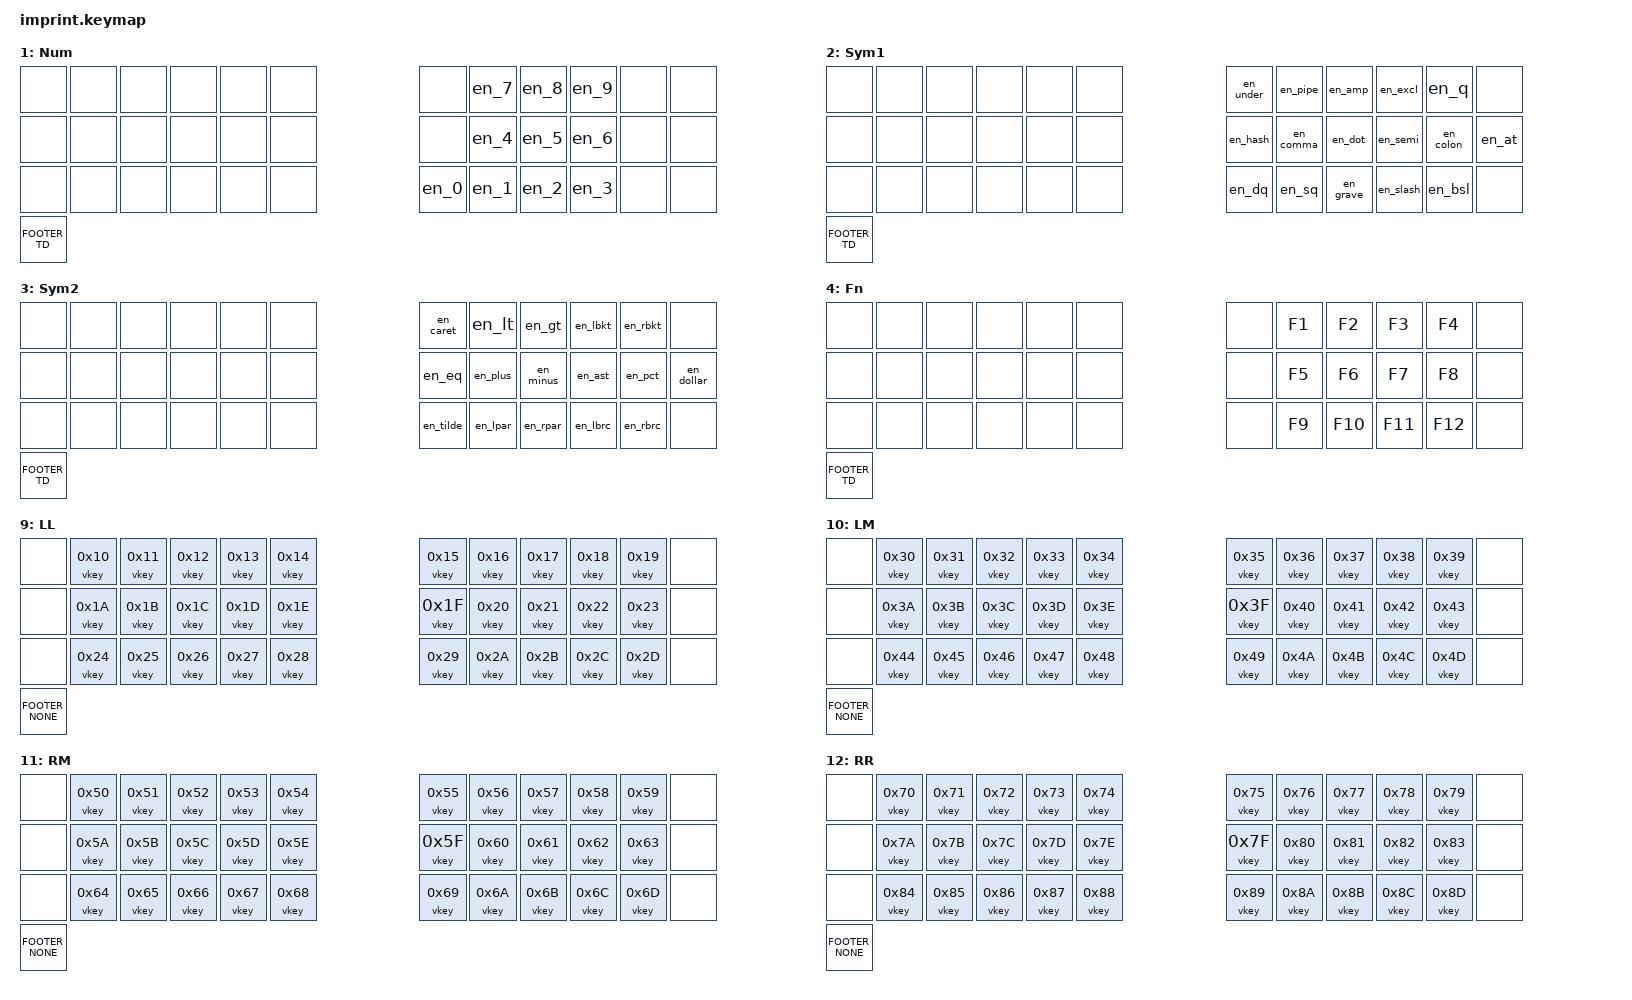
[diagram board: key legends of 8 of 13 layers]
#include <input/processors.dtsi>
#include <dt-bindings/zmk/input_transform.h>
#include <behaviors.dtsi>
#include <dt-bindings/zmk/keys.h>

#include "behavior_macros.h"

// https://github.com/zmkfirmware/zmk/pull/1811
&mt {
  hold-while-undecided;
};

// The left trackball always scrolls.
&trackball_central_listener {
  input-processors = TRACKBALL_SCROLL_PROCESSORS;
};

/ {
  chosen {
    zmk,matrix-transform = &imprint_letters_only_full_bottom_row;
  };
  combos {
    compatible = "zmk,combos";
    #include "combos.dtsi"
  };
  macros {
    #include "macros.dtsi"
  };
  behaviors {
    #include "imprint_behaviors.dtsi"
  };
  keymap {
    compatible = "zmk,keymap";

    // display-name matches [A-Za-z][A-Za-z0-9]{0,3} and is unique: only its
    // first 4 bytes reach the Prospector Dongle, and keymap-drawer silently
    // drops a layer whose name repeats. Canonical names, reasons and sources:
    // docs/glossary.md, entry "layer".
    DEFAULT_LAYER {
      display-name = "Base";
      bindings = <
        &kp EIJI    &al_q               &al_w              &al_e              &al_r             &al_t                    &al_y  &al_u     &al_i     &al_o      &al_p       &kp KANA
        &kp SPACE   &al_a               &al_s              &al_d              &al_f             &al_g                    &al_h  &al_j     &al_k     &al_l      &vkey 0x01     &kp BACKSPACE
        &kp ESCAPE  &al_z               &al_x              &al_c              &al_v             &al_b                    &al_n  &al_m     &ar_up    &kp TAB    &kp DELETE  &kp RETURN
        &none       MO_LAYER(FUNCTION)  MO_LAYER(SYMBOL2)  MO_LAYER(SYMBOL1)  MO_LAYER(NUMBER)                                  &ar_left  &ar_down  &ar_right  &none       &none
                                                               TU_LL  TU_LM  &none                    &none  TU_RM  TU_RR
                                                               TD_LL  TD_LM  &none                    &none  TD_RM  TD_RR
      >;
    };
    NUMBER_LAYER {
      display-name = "Num";
      bindings = <
        &none  &none  &none  &none  &none  &none                    &none  &en_7  &en_8  &en_9  &none  &none
        &none  &none  &none  &none  &none  &none                    &none  &en_4  &en_5  &en_6  &none  &none
        &none  &none  &none  &none  &none  &none                    &en_0  &en_1  &en_2  &en_3  &none  &none
        FOOTER_TD
      >;
    };
    SYMBOL1_LAYER {
      display-name = "Sym1";
      bindings = <
        &none  &none  &none  &none  &none  &none                    &en_under  &en_pipe   &en_amp    &en_excl   &en_q      &none
        &none  &none  &none  &none  &none  &none                    &en_hash   &en_comma  &en_dot    &en_semi   &en_colon  &en_at
        &none  &none  &none  &none  &none  &none                    &en_dq     &en_sq     &en_grave  &en_slash  &en_bsl    &none
        FOOTER_TD
      >;
    };
    SYMBOL2_LAYER {
      display-name = "Sym2";
      bindings = <
        &none  &none  &none  &none  &none  &none                    &en_caret  &en_lt    &en_gt     &en_lbkt  &en_rbkt  &none
        &none  &none  &none  &none  &none  &none                    &en_eq     &en_plus  &en_minus  &en_ast   &en_pct   &en_dollar
        &none  &none  &none  &none  &none  &none                    &en_tilde  &en_lpar  &en_rpar   &en_lbrc  &en_rbrc  &none
        FOOTER_TD
      >;
    };
    FUNCTION_LAYER {
      display-name = "Fn";
      bindings = <
        &none  &none  &none  &none  &none  &none                    &none  &kp F1  &kp F2   &kp F3   &kp F4   &none
        &none  &none  &none  &none  &none  &none                    &none  &kp F5  &kp F6   &kp F7   &kp F8   &none
        &none  &none  &none  &none  &none  &none                    &none  &kp F9  &kp F10  &kp F11  &kp F12  &none
        FOOTER_TD
      >;
    };
    // Arrow sub-layers, entered by holding an arrow key (ar_*). A display-name
    // names that arrow key (the node's *_ARROW), not what the layer sends,
    // which may change.
    LEFT_ARROW_LAYER {
      display-name = "LArr";
      bindings = <
        ROW_NONE
        ROW_NONE
        ROW_NONE
        &none  &none  &none  &none  &none                    &none  &kp HOME  &none  &none  &none
        THUMB_TD
      >;
    };
    RIGHT_ARROW_LAYER {
      display-name = "RArr";
      bindings = <
        ROW_NONE
        ROW_NONE
        ROW_NONE
        &none  &none  &none  &none  &none                    &none  &kp END  &none  &none  &none
        THUMB_TD
      >;
    };
    UP_ARROW_LAYER {
      display-name = "UArr";
      bindings = <
        ROW_NONE
        ROW_NONE
        ROW_NONE
        &none  &none  &none  &none  &none                    &kp PAGE_UP  &none  &none  &none  &none
        THUMB_TD
      >;
    };
    DOWN_ARROW_LAYER {
      display-name = "DArr";
      bindings = <
        ROW_NONE
        ROW_NONE
        ROW_NONE
        &none  &none  &none  &none  &none                    &kp PAGE_DOWN  &none  &none  &none  &none
        THUMB_TD
      >;
    };
    T_LL_LAYER {
      display-name = "LL";
      bindings = <
        &none  &vkey 0x10  &vkey 0x11  &vkey 0x12  &vkey 0x13  &vkey 0x14                    &vkey 0x15  &vkey 0x16  &vkey 0x17    &vkey 0x18    &vkey 0x19    &none
        &none  &vkey 0x1A  &vkey 0x1B  &vkey 0x1C  &vkey 0x1D  &vkey 0x1E                    &vkey 0x1F  &vkey 0x20  &vkey 0x21    &vkey 0x22    &vkey 0x23  &none
        &none  &vkey 0x24  &vkey 0x25  &vkey 0x26  &vkey 0x27  &vkey 0x28                    &vkey 0x29  &vkey 0x2A  &vkey 0x2B  &vkey 0x2C  &vkey 0x2D  &none
        FOOTER_NONE
      >;
    };
    T_LM_LAYER {
      display-name = "LM";
      bindings = <
        &none  &vkey 0x30  &vkey 0x31  &vkey 0x32  &vkey 0x33  &vkey 0x34                    &vkey 0x35  &vkey 0x36  &vkey 0x37    &vkey 0x38    &vkey 0x39    &none
        &none  &vkey 0x3A  &vkey 0x3B  &vkey 0x3C  &vkey 0x3D  &vkey 0x3E                    &vkey 0x3F  &vkey 0x40  &vkey 0x41    &vkey 0x42    &vkey 0x43  &none
        &none  &vkey 0x44  &vkey 0x45  &vkey 0x46  &vkey 0x47  &vkey 0x48                    &vkey 0x49  &vkey 0x4A  &vkey 0x4B  &vkey 0x4C  &vkey 0x4D  &none
        FOOTER_NONE
      >;
    };
    T_RM_LAYER {
      display-name = "RM";
      bindings = <
        &none  &vkey 0x50  &vkey 0x51  &vkey 0x52  &vkey 0x53  &vkey 0x54                    &vkey 0x55  &vkey 0x56  &vkey 0x57    &vkey 0x58    &vkey 0x59    &none
        &none  &vkey 0x5A  &vkey 0x5B  &vkey 0x5C  &vkey 0x5D  &vkey 0x5E                    &vkey 0x5F  &vkey 0x60  &vkey 0x61    &vkey 0x62    &vkey 0x63  &none
        &none  &vkey 0x64  &vkey 0x65  &vkey 0x66  &vkey 0x67  &vkey 0x68                    &vkey 0x69  &vkey 0x6A  &vkey 0x6B  &vkey 0x6C  &vkey 0x6D  &none
        FOOTER_NONE
      >;
    };
    T_RR_LAYER {
      display-name = "RR";
      bindings = <
        &none  &vkey 0x70  &vkey 0x71  &vkey 0x72  &vkey 0x73  &vkey 0x74                    &vkey 0x75  &vkey 0x76  &vkey 0x77    &vkey 0x78    &vkey 0x79    &none
        &none  &vkey 0x7A  &vkey 0x7B  &vkey 0x7C  &vkey 0x7D  &vkey 0x7E                    &vkey 0x7F  &vkey 0x80  &vkey 0x81    &vkey 0x82    &vkey 0x83  &none
        &none  &vkey 0x84  &vkey 0x85  &vkey 0x86  &vkey 0x87  &vkey 0x88                    &vkey 0x89  &vkey 0x8A  &vkey 0x8B  &vkey 0x8C  &vkey 0x8D  &none
        FOOTER_NONE
      >;
    };
  };
};
